# STM32H743 register map
File version: 2.4
CPU: CM7 r0p1, little endian, MPU, FPU, 4 interrupt priority bits
Registers are 32-bit, read-write, reset 0x0 unless marked. A register's access mark holds for its fields unless they carry their own. Offsets are from the block's base; [hi:lo] are bit positions; {n}, {i} and the like mark numbered series.

## DELAY_Block_SDMMC1
Base 0x52008000
Same registers: DELAY_Block_SDMMC2 0x48022800, DELAY_Block_QUADSPI 0x52006000
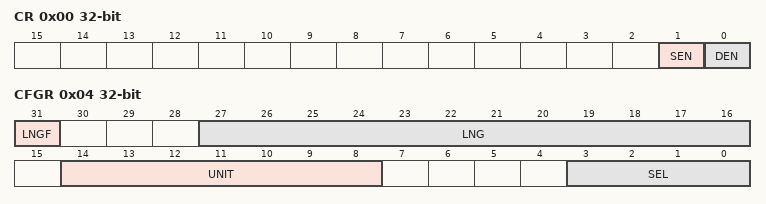
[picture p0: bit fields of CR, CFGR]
0x00 CR — DLYB control register
  [1] SEN — Sampler length enable bit
  [0] DEN — Delay block enable bit
0x04 CFGR — DLYB configuration register
  [31] LNGF — Length valid flag
  [27:16] LNG — Delay line length value
  [14:8] UNIT — Delay Defines the delay of a Unit delay cell
  [3:0] SEL — Select the phase for the Output clock

## DCMI — Digital camera interface
Base 0x48020000
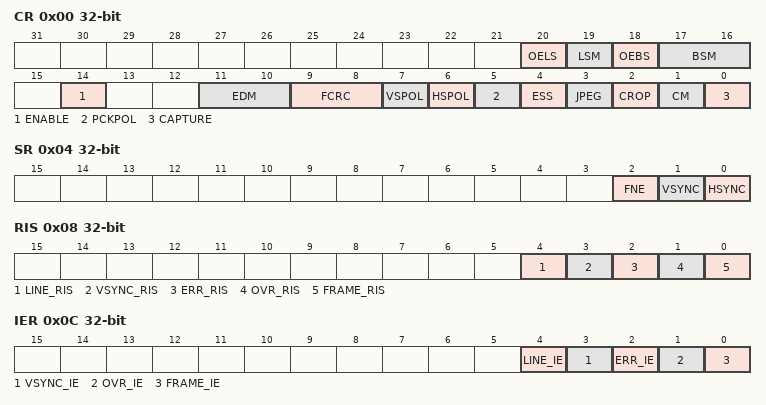
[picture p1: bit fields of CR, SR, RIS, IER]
0x00 CR — control register 1
  [20] OELS — Odd/Even Line Select (Line Select Start)
  [19] LSM — Line Select mode
  [18] OEBS — Odd/Even Byte Select (Byte Select Start)
  [17:16] BSM — Byte Select mode
  [14] ENABLE — DCMI enable
  [11:10] EDM — Extended data mode
  [9:8] FCRC — Frame capture rate control
  [7] VSPOL — Vertical synchronization polarity
  [6] HSPOL — Horizontal synchronization polarity
  [5] PCKPOL — Pixel clock polarity
  [4] ESS — Embedded synchronization select
  [3] JPEG — JPEG format
  [2] CROP — Crop feature
  [1] CM — Capture mode
  [0] CAPTURE — Capture enable
0x04 SR ro — status register
  [2] FNE — FIFO not empty
  [1] VSYNC
  [0] HSYNC
0x08 RIS ro — raw interrupt status register
  [4] LINE_RIS — Line raw interrupt status
  [3] VSYNC_RIS — VSYNC raw interrupt status
  [2] ERR_RIS — Synchronization error raw interrupt status
  [1] OVR_RIS — Overrun raw interrupt status
  [0] FRAME_RIS — Capture complete raw interrupt status
0x0C IER — interrupt enable register
  [4] LINE_IE — Line interrupt enable
  [3] VSYNC_IE — VSYNC interrupt enable
  [2] ERR_IE — Synchronization error interrupt enable
  [1] OVR_IE — Overrun interrupt enable
  [0] FRAME_IE — Capture complete interrupt enable
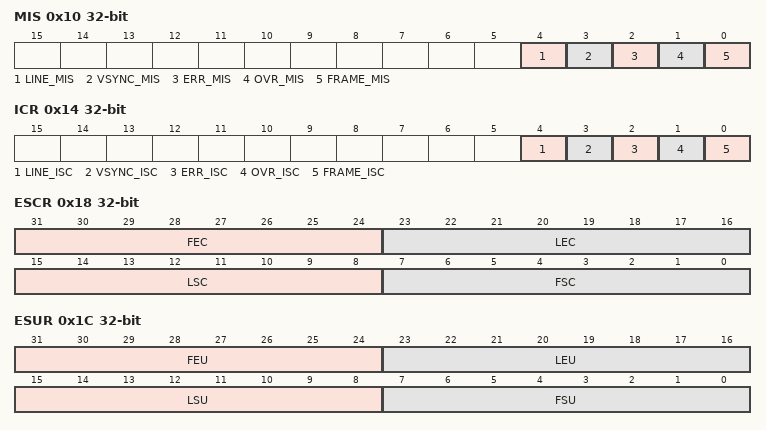
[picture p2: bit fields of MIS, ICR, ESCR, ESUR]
0x10 MIS ro — masked interrupt status register
  [4] LINE_MIS — Line masked interrupt status
  [3] VSYNC_MIS — VSYNC masked interrupt status
  [2] ERR_MIS — Synchronization error masked interrupt status
  [1] OVR_MIS — Overrun masked interrupt status
  [0] FRAME_MIS — Capture complete masked interrupt status
0x14 ICR wo — interrupt clear register
  [4] LINE_ISC — line interrupt status clear
  [3] VSYNC_ISC — Vertical synch interrupt status clear
  [2] ERR_ISC — Synchronization error interrupt status clear
  [1] OVR_ISC — Overrun interrupt status clear
  [0] FRAME_ISC — Capture complete interrupt status clear
0x18 ESCR — embedded synchronization code register
  [31:24] FEC — Frame end delimiter code
  [23:16] LEC — Line end delimiter code
  [15:8] LSC — Line start delimiter code
  [7:0] FSC — Frame start delimiter code
0x1C ESUR — embedded synchronization unmask register
  [31:24] FEU — Frame end delimiter unmask
  [23:16] LEU — Line end delimiter unmask
  [15:8] LSU — Line start delimiter unmask
  [7:0] FSU — Frame start delimiter unmask
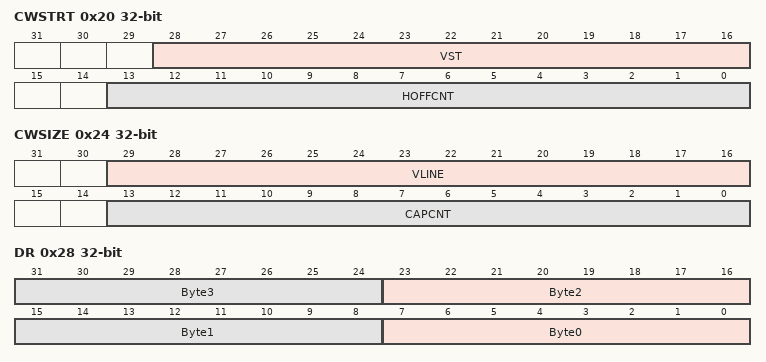
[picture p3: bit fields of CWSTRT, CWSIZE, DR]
0x20 CWSTRT — crop window start
  [28:16] VST — Vertical start line count
  [13:0] HOFFCNT — Horizontal offset count
0x24 CWSIZE — crop window size
  [29:16] VLINE — Vertical line count
  [13:0] CAPCNT — Capture count
0x28 DR ro — data register
  [8n+7:8n] Byte{n} (n=0..3) — Data byte {n}

## OTG1_HS_PWRCLK — USB 1 on the go high speed
Base 0x40040E00
Same registers: OTG2_HS_PWRCLK 0x40080E00
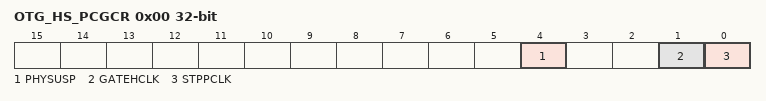
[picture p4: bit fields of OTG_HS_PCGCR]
0x00 OTG_HS_PCGCR — Power and clock gating control register
  [4] PHYSUSP — PHY suspended
  [1] GATEHCLK
  [0] STPPCLK — Stop PHY clock

## Ethernet_MTL — Ethernet: MTL mode register (MTL)
Base 0x40028C00
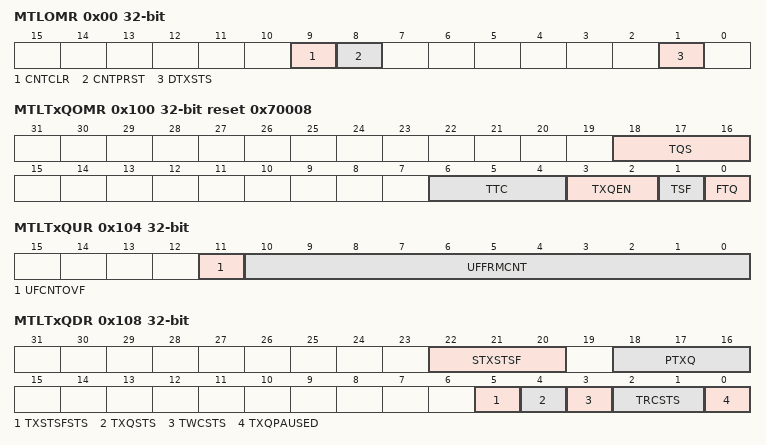
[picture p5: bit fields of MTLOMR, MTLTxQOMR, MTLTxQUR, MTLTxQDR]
0x00 MTLOMR — Operating mode Register
  [9] CNTCLR, [8] CNTPRST, [1] DTXSTS
0x20 MTLISR ro — Interrupt status Register
  [0] Q0IS — Queue interrupt status
0x100 MTLTxQOMR access per field reset 0x70008 — Tx queue operating mode Register
  [18:16] TQS rw — Transmit Queue Size
  [6:4] TTC rw — Transmit Threshold Control
  [3:2] TXQEN ro — Transmit Queue Enable
  [1] TSF rw — Transmit Store and Forward
  [0] FTQ rw — Flush Transmit Queue
0x104 MTLTxQUR ro — Tx queue underflow register
  [11] UFCNTOVF
  [10:0] UFFRMCNT — Underflow Packet Counter
0x108 MTLTxQDR ro — Tx queue debug Register
  [22:20] STXSTSF, [18:16] PTXQ, [5] TXSTSFSTS, [4] TXQSTS, [3] TWCSTS, [2:1] TRCSTS, [0] TXQPAUSED
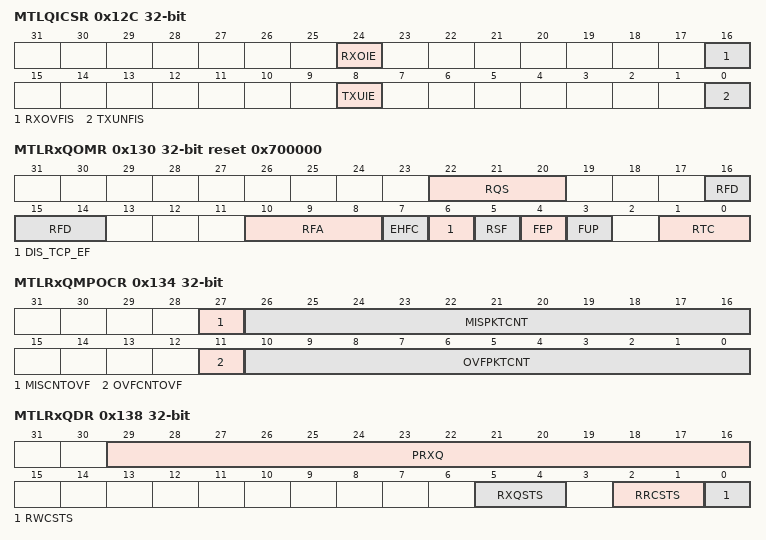
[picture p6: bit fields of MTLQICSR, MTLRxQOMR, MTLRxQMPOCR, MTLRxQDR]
0x12C MTLQICSR — Queue interrupt control status Register
  [24] RXOIE, [16] RXOVFIS, [8] TXUIE, [0] TXUNFIS
0x130 MTLRxQOMR access per field reset 0x700000 — Rx queue operating mode register
  [22:20] RQS ro, [16:14] RFD rw, [10:8] RFA rw, [7] EHFC rw, [6] DIS_TCP_EF rw, [5] RSF rw, [4] FEP rw, [3] FUP rw, [1:0] RTC rw
0x134 MTLRxQMPOCR ro — Rx queue missed packet and overflow counter register
  [27] MISCNTOVF, [26:16] MISPKTCNT, [11] OVFCNTOVF, [10:0] OVFPKTCNT
0x138 MTLRxQDR ro — Rx queue debug register
  [29:16] PRXQ, [5:4] RXQSTS, [2:1] RRCSTS, [0] RWCSTS
